# MCXA153 register map
Vendor: nxp.com; File version: 1.0
CPU: CM33 r2p0, little endian, no MPU, no FPU, VTOR, 3 interrupt priority bits
Registers are 32-bit, read-write, reset 0x0 unless marked. A register's access mark holds for its fields unless they carry their own. Offsets are from the block's base; [hi:lo] are bit positions; {n}, {i} and the like mark numbered series; 'fields as' and 'values as' point back to an identical list.

## SCnSCB — System Control not in System Control Block
Base 0xE000E000
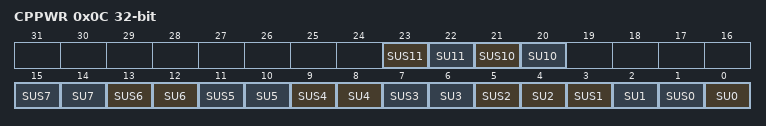
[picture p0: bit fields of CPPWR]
0x0C CPPWR reset not defined — Coprocessor Power Control Register
  [23] SUS11 — State UNKNOWN Secure only 11.
  [22] SU11 — State UNKNOWN 11.
  [21] SUS10 — State UNKNOWN Secure only 10.
    0=SECURE_AND_NON_SECURE (The SU10 field is accessible from both Security states.); 1=SECURE_ONLY (The SU10 field is only accessible from the Secure state.)
  [20] SU10 — State UNKNOWN 10.
    0=UNKNOWN_NOT_PERMITTED (The floating-point state is not permitted to become UNKNOWN.); 1=UNKNOWN_PERMITTED (The floating-point state is permitted to become UNKNOWN)
  [2n+1] SUS{n} (n=2..7) — State UNKNOWN Secure only {n}.
    0=SECURE_AND_NON_SECURE (The SU{n} field is accessible from both Security states.); 1=SECURE_ONLY (The SU{n} field is only accessible from the Secure state.)
  [2n] SU{n} (n=0..7) — State UNKNOWN {n}.
    0=UNKNOWN_NOT_PERMITTED (The coprocessor state is not permitted to become UNKNOWN.); 1=UNKNOWN_PERMITTED (The coprocessor state is permitted to become UNKNOWN.)
  [3] SUS1 — State UNKNOWN Secure only 1.
    0=SECURE_AND_NON_SECURE (The SU7 field is accessible from both Security states.); 1=SECURE_ONLY (The SU7 field is only accessible from the Secure state.)
  [1] SUS0 — State UNKNOWN Secure only 0.
    0=SECURE_AND_NON_SECURE (The SU0 field is accessible from both Security states.); 1=SECURE_ONLY (The SU0 field is only accessible from the Secure state.)

## SysTick — M33 Systick module
Base 0xE000E010
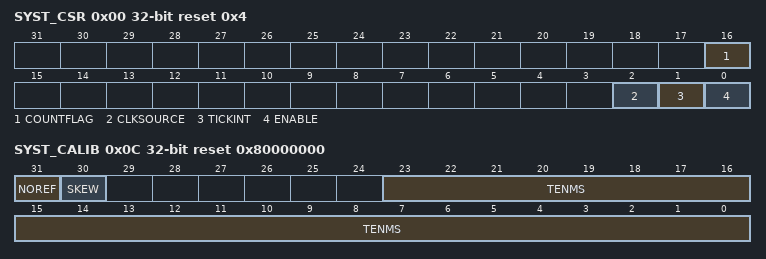
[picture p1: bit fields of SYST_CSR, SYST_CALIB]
0x00 SYST_CSR reset 0x4 — SysTick Control and Status Register
  [16] COUNTFLAG — Returns 1 if timer counted to 0 since the last read of this register.
  [2] CLKSOURCE — Clock source selection.
    0=EXTERNAL_CLOCK; 1=PROCESSOR_CLOCK
  [1] TICKINT — Enable Systick interrupt.
    0=INTERRUPT_DISABLED (counting down to 0 does not assert the SysTick exception request); 1=INTERRUPT_ENABLED (counting down to 0 asserts the SysTick exception request)
  [0] ENABLE — Enable/disable systick counter
    0=COUNTER_DISABLED; 1=COUNTER_ENABLED
0x04 SYST_RVR — SysTick Reload Value Register
  [23:0] RELOAD — Value to load into the SysTick Current Value Register when the counter reaches 0
0x08 SYST_CVR — SysTick Current Value Register
  [23:0] CURRENT — Reads current counter value at the time the register is accessed. Any write to the register clears the register to 0.
0x0C SYST_CALIB ro reset 0x80000000 — SysTick Calibration Value Register
  [31] NOREF — Indicates whether the device provides an alternative reference clock
    0=CLOCK_PROVIDED (The alternative reference clock is provided); 1=CLOCK_DISABLED (The alternative reference clock is not provided)
  [30] SKEW — Indicates whether the TENMS value is exact
    0=EXACT_VALUE (10ms calibration value is exact); 1=INEXACT_VALUE (10ms calibration value is inexact, because of the clock frequency)
  [23:0] TENMS — Reload value to use for 10ms timing

## NVIC — Nested Vectored Interrupt Controller
Base 0xE000E100
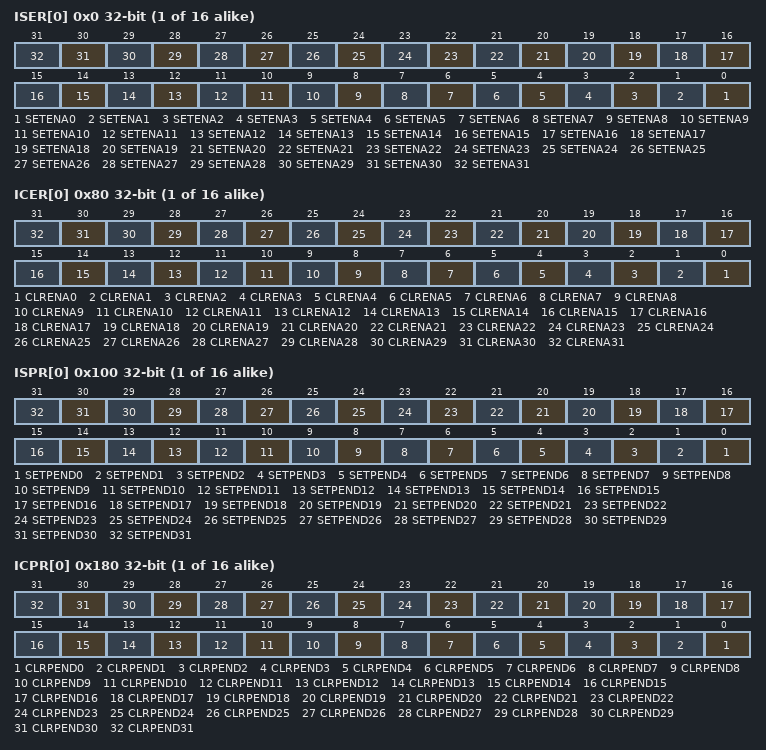
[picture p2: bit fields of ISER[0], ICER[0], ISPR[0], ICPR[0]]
{0x0+4i} ISER[{i}] (i=0..15) — Interrupt Set Enable Register
  [all] fields
    0=DISABLED (Write: No effect; Read: Interrupt 32n+m disabled); 1=ENABLED (Write: Enable interrupt 32n+m; Read: Interrupt 32n+m enabled)
  [n] SETENA{n} (n=0..31) — Interrupt set-enable bits.
{0x80+4i} ICER[{i}] (i=0..15) — Interrupt Clear Enable Register
  [all] fields
    values as the fields of ISER[0]
  [n] CLRENA{n} (n=0..31) — Interrupt clear-enable bits.
{0x100+4i} ISPR[{i}] (i=0..15) — Interrupt Set Pending Register
  [all] fields
    0=NOT_PENDING (Write: No effect; Read: Interrupt 32n+m is not pending); 1=PENDING (Write: Pend interrupt 32n+m; Read: Interrupt 32n+m pending)
  [n] SETPEND{n} (n=0..31) — Interrupt set-pending bits.
{0x180+4i} ICPR[{i}] (i=0..15) — Interrupt Clear Pending Register
  [all] fields
    0=NOT_PENDING (Write: No effect; Read: Interrupt 32n+m is not pending); 1=PENDING (Write: Clear pending state of interrupt 32n+m; Read: Interrupt 32n+m is pending)
  [n] CLRPEND{n} (n=0..31) — Interrupt clear-pending bits.
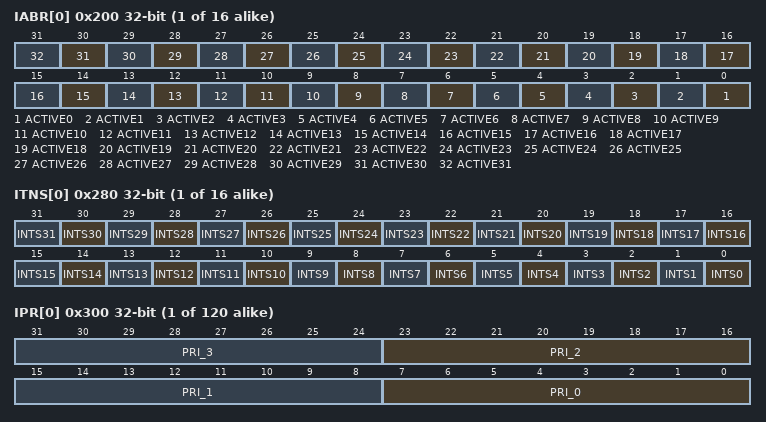
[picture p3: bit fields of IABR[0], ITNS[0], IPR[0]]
{0x200+4i} IABR[{i}] (i=0..15) reset not defined — Interrupt Active Bit Register
  [all] fields
    0=NOT_ACTIVE (The interrupt is not active.); 1=ACTIVE (The interrupt is active.)
  [n] ACTIVE{n} (n=0..31) — Active state bits.
{0x280+4i} ITNS[{i}] (i=0..15) reset not defined — Interrupt Target Non-secure Register
  [all] fields
    0=SECURE_STATE (The interrupt targets Secure state.); 1=NON_SECURE_STATE (The interrupt targets Non-secure state.)
  [n] INTS{n} (n=0..31) — Interrupt Targets Non-secure bits.
{0x300+4i} IPR[{i}] (i=0..119) reset not defined — Interrupt Priority Register
  [8n+7:8n] PRI_{n} (n=0..3)
0xE00 STIR wo — Software Trigger Interrupt Register
  [8:0] INTID — Interrupt ID of the interrupt to trigger, in the range 0-479.

## SAU — Security Attribution Unit
Base 0xE000EDD0
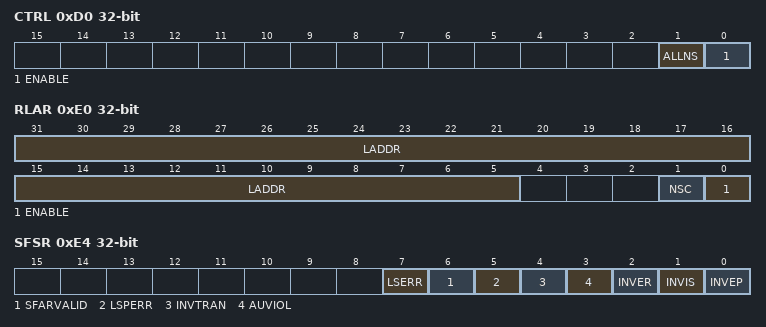
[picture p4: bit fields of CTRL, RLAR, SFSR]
0xD0 CTRL — Security Attribution Unit Control Register
  [1] ALLNS — All Non-secure.
    0=SECURED_MEMORY (Memory is marked as Secure and is not Non-secure callable.); 1=NON_SECURED_MEMORY (Memory is marked as Non-secure.)
  [0] ENABLE — Enable. Enables the SAU. This bit is RAZ/WI when the Security Extension is implemented without an SAU region.
    0=DISABLED (The SAU is disabled.); 1=ENABLED (The SAU is enabled.)
0xD4 TYPE — Security Attribution Unit Type Register
  [7:0] SREGION — SAU regions. The number of implemented SAU regions.
0xD8 RNR reset not defined — Security Attribution Unit Region Number Register
  [7:0] REGION — Region number.
0xDC RBAR reset not defined — Security Attribution Unit Region Base Address Register
  [31:5] BADDR — Base address. Holds bits[31:5] of the base address for the selected SAU region. Bits[4:0] of the base address are defined as 0x00.
0xE0 RLAR reset not defined — Security Attribution Unit Region Limit Address Register
  [31:5] LADDR — Limit address. Holds bits[31:5] of the limit address for the selected SAU region. Bits[4:0] of the limit address are defined as 0x1F.
  [1] NSC — Non-secure callable. Controls whether Non-secure state is permitted to execute an SG instruction from this region.
    0=NOT_NON_SECURE_CALLABLE (Region is not Non-secure callable.); 1=NON_SECURE_CALLABLE (Region is Non-secure callable.)
  [0] ENABLE — Enable. SAU region enable.
    0=ENABLED (SAU region is enabled.); 1=DISABLED (SAU region is disabled.)
0xE4 SFSR — Secure Fault Status Register
  [7] LSERR — Lazy state error flag.
    0=NO_ERROR (Error has not occurred); 1=ERROR (Error has occurred.)
  [6] SFARVALID — Secure fault address valid.
    0=NOT_VALID (SFAR content not valid.); 1=VALID (SFAR content valid.)
  [5] LSPERR — Lazy state preservation error flag.
    0=NO_ERROR (Error has not occurred.); 1=ERROR (Error has occurred.)
  [4] INVTRAN — Invalid transition flag.
    values as LSPERR
  [3] AUVIOL — Attribution unit violation flag.
    values as LSPERR
  [2] INVER — Invalid exception return flag.
    values as LSPERR
  [1] INVIS — Invalid integrity signature flag.
    values as LSPERR
  [0] INVEP — Invalid entry point.
    values as LSPERR
0xE8 SFAR reset not defined — Secure Fault Address Register
  [31:0] ADDRESS — When the SFARVALID bit of the SFSR is set to 1, this field holds the address of an access that caused an SAU violation.
